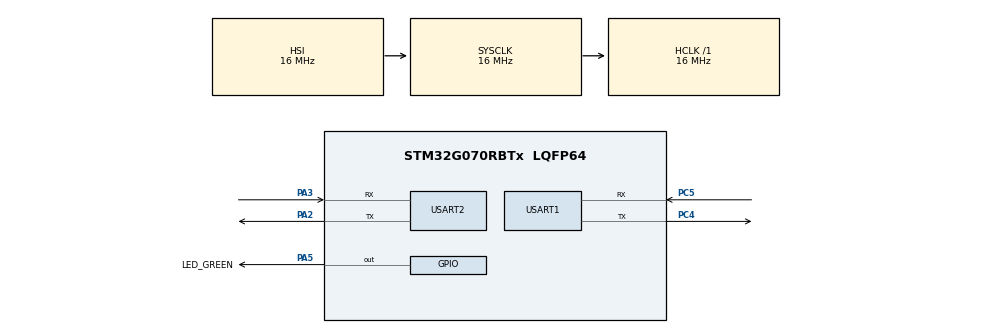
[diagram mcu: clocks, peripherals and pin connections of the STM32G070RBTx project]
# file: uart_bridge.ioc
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FREERTOS.MEMORY_ALLOCATION=2
FREERTOS.Queues01=q_to_uart1,32,uint8_t,0,Static,q_to_uart1Buffer,q_to_uart1ControlBlock;q_to_uart2,32,uint8_t,0,Static,q_to_uart2Buffer,q_to_uart2ControlBlock
FREERTOS.Tasks01=defaultTask,-2,128,StartDefaultTask,Default,NULL,Static,defaultTaskBuffer,defaultTaskControlBlock;uart1_task,0,128,uart1_task_ef,Default,NULL,Static,uart1_taskBuffer,uart1_taskControlBlock;uart2_task,0,128,uart2_task_ef,Default,NULL,Static,uart2_taskBuffer,uart2_taskControlBlock
FREERTOS.configTOTAL_HEAP_SIZE=4096
FREERTOS.configUSE_PREEMPTION=0
Mcu.Family=STM32G0
Mcu.Name=STM32G070RBTx
Mcu.Package=LQFP64
NVIC.TIM17_IRQn=true\:3\:0\:false\:false\:true\:false\:false\:true\:true
NVIC.TimeBase=TIM17_IRQn
NVIC.TimeBaseIP=TIM17
NVIC.USART1_IRQn=true\:3\:0\:true\:false\:true\:true\:true\:true\:true
NVIC.USART2_IRQn=true\:3\:0\:false\:false\:true\:true\:true\:true\:true
PA13.GPIO_Label=TMS
PA13.Mode=Serial_Wire
PA13.Signal=SYS_SWDIO
PA14-BOOT0.GPIO_Label=TCK
PA14-BOOT0.Mode=Serial_Wire
PA14-BOOT0.Signal=SYS_SWCLK
PA2.GPIO_PuPd=GPIO_PULLUP
PA2.Mode=Asynchronous
PA2.Signal=USART2_TX
PA3.GPIO_PuPd=GPIO_PULLUP
PA3.Mode=Asynchronous
PA3.Signal=USART2_RX
PA5.GPIO_Label=LED_GREEN
PA5.GPIO_Speed=GPIO_SPEED_FREQ_HIGH
PA5.Signal=GPIO_Output
PC13.Mode=SYS_WakeUp1
PC13.Signal=SYS_WKUP2
PC14-OSC32_IN\ (PC14).Mode=LSE-External-Oscillator
PC14-OSC32_IN\ (PC14).Signal=RCC_OSC32_IN
PC15-OSC32_OUT\ (PC15).Mode=LSE-External-Oscillator
PC15-OSC32_OUT\ (PC15).Signal=RCC_OSC32_OUT
PC4.Mode=Asynchronous
PC4.Signal=USART1_TX
PC5.Mode=Asynchronous
PC5.Signal=USART1_RX
PF0-OSC_IN\ (PF0).GPIO_Label=MCO
PF0-OSC_IN\ (PF0).Mode=HSE-External-Clock-Source
PF0-OSC_IN\ (PF0).Signal=RCC_OSC_IN
ProjectManager.HeapSize=0x2000
ProjectManager.StackSize=0x4000
ProjectManager.TargetToolchain=MDK-ARM V5.32
RCC.AHBFreq_Value=16000000
RCC.CortexFreq_Value=16000000
RCC.EXTERNAL_CLOCK_VALUE=12288000
RCC.HCLKFreq_Value=16000000
RCC.HSE_VALUE=8000000
RCC.HSI_VALUE=16000000
RCC.SYSCLKFreq_VALUE=16000000
RCC.VCOOutputFreq_Value=128000000
USART1.VirtualMode-Asynchronous=VM_ASYNC
USART2.VirtualMode-Asynchronous=VM_ASYNC
USART2.WordLength=WORDLENGTH_8B
VP_FREERTOS_VS_CMSIS_V1.Mode=CMSIS_V1
VP_SYS_VS_DBSignals.Mode=DisableDeadBatterySignals
VP_SYS_VS_tim17.Mode=TIM17
board=NUCLEO-G070RB

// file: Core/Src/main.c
/* USER CODE BEGIN Header */
/**
 ******************************************************************************
 * @file           : main.c
 * @brief          : Main program body
 ******************************************************************************
 * @attention
 *
 * Copyright (c) 2024 STMicroelectronics.
 * All rights reserved.
 *
 * This software is licensed under terms that can be found in the LICENSE file
 * in the root directory of this software component.
 * If no LICENSE file comes with this software, it is provided AS-IS.
 *
 ******************************************************************************
 */
/* USER CODE END Header */
#include "main.h"
#include "cmsis_os.h"

UART_HandleTypeDef huart1;
UART_HandleTypeDef huart2;

osThreadId defaultTaskHandle;
uint32_t defaultTaskBuffer[128];
osStaticThreadDef_t defaultTaskControlBlock;
osThreadId uart1_taskHandle;
uint32_t uart1_taskBuffer[128];
osStaticThreadDef_t uart1_taskControlBlock;
osThreadId uart2_taskHandle;
uint32_t uart2_taskBuffer[128];
osStaticThreadDef_t uart2_taskControlBlock;
osMessageQId q_to_uart1Handle;
uint8_t q_to_uart1Buffer[32 * sizeof(uint8_t)];
osStaticMessageQDef_t q_to_uart1ControlBlock;
osMessageQId q_to_uart2Handle;
uint8_t q_to_uart2Buffer[32 * sizeof(uint8_t)];
osStaticMessageQDef_t q_to_uart2ControlBlock;

void SystemClock_Config(void);
static void MX_GPIO_Init(void);
static void MX_USART1_UART_Init(void);
static void MX_USART2_UART_Init(void);
void StartDefaultTask(void const *argument);
void uart1_task_ef(void const *argument);
void uart2_task_ef(void const *argument);

int main(void)
{

  /* MCU Configuration--------------------------------------------------------*/

  /* Reset of all peripherals, Initializes the Flash interface and the Systick. */
  HAL_Init();

  /* Configure the system clock */
  SystemClock_Config();

  /* Initialize all configured peripherals */
  MX_GPIO_Init();
  MX_USART1_UART_Init();
  MX_USART2_UART_Init();

  /* Create the queue(s) */
  /* definition and creation of q_to_uart1 */
  osMessageQStaticDef(q_to_uart1, 32, uint8_t, q_to_uart1Buffer, &q_to_uart1ControlBlock);
  q_to_uart1Handle = osMessageCreate(osMessageQ(q_to_uart1), NULL);

  /* definition and creation of q_to_uart2 */
  osMessageQStaticDef(q_to_uart2, 32, uint8_t, q_to_uart2Buffer, &q_to_uart2ControlBlock);
  q_to_uart2Handle = osMessageCreate(osMessageQ(q_to_uart2), NULL);

  /* Create the thread(s) */
  /* definition and creation of defaultTask */
  osThreadStaticDef(defaultTask, StartDefaultTask, osPriorityLow, 0, 128, defaultTaskBuffer, &defaultTaskControlBlock);
  defaultTaskHandle = osThreadCreate(osThread(defaultTask), NULL);

  /* definition and creation of uart1_task */
  osThreadStaticDef(uart1_task, uart1_task_ef, osPriorityNormal, 0, 128, uart1_taskBuffer, &uart1_taskControlBlock);
  uart1_taskHandle = osThreadCreate(osThread(uart1_task), NULL);

  /* definition and creation of uart2_task */
  osThreadStaticDef(uart2_task, uart2_task_ef, osPriorityNormal, 0, 128, uart2_taskBuffer, &uart2_taskControlBlock);
  uart2_taskHandle = osThreadCreate(osThread(uart2_task), NULL);

  /* Start scheduler */
  osKernelStart();

  /* We should never get here as control is now taken by the scheduler */

  /* Infinite loop */
  while (1)
  {

  }
}

void SystemClock_Config(void)
{
  RCC_OscInitTypeDef RCC_OscInitStruct = {0};
  RCC_ClkInitTypeDef RCC_ClkInitStruct = {0};

  /** Configure the main internal regulator output voltage
   */
  HAL_PWREx_ControlVoltageScaling(PWR_REGULATOR_VOLTAGE_SCALE1);

  /** Initializes the RCC Oscillators according to the specified parameters
   * in the RCC_OscInitTypeDef structure.
   */
  RCC_OscInitStruct.OscillatorType = RCC_OSCILLATORTYPE_HSI;
  RCC_OscInitStruct.HSIState = RCC_HSI_ON;
  RCC_OscInitStruct.HSIDiv = RCC_HSI_DIV1;
  RCC_OscInitStruct.HSICalibrationValue = RCC_HSICALIBRATION_DEFAULT;
  RCC_OscInitStruct.PLL.PLLState = RCC_PLL_NONE;
  if (HAL_RCC_OscConfig(&RCC_OscInitStruct) != HAL_OK)
  {
    Error_Handler();
  }

  /** Initializes the CPU, AHB and APB buses clocks
   */
  RCC_ClkInitStruct.ClockType = RCC_CLOCKTYPE_HCLK | RCC_CLOCKTYPE_SYSCLK | RCC_CLOCKTYPE_PCLK1;
  RCC_ClkInitStruct.SYSCLKSource = RCC_SYSCLKSOURCE_HSI;
  RCC_ClkInitStruct.AHBCLKDivider = RCC_SYSCLK_DIV1;
  RCC_ClkInitStruct.APB1CLKDivider = RCC_HCLK_DIV1;

  if (HAL_RCC_ClockConfig(&RCC_ClkInitStruct, FLASH_LATENCY_0) != HAL_OK)
  {
    Error_Handler();
  }
}

static void MX_USART1_UART_Init(void)
{

  huart1.Instance = USART1;
  huart1.Init.BaudRate = 9600;
  huart1.Init.WordLength = UART_WORDLENGTH_8B;
  huart1.Init.StopBits = UART_STOPBITS_1;
  huart1.Init.Parity = UART_PARITY_NONE;
  huart1.Init.Mode = UART_MODE_TX_RX;
  huart1.Init.HwFlowCtl = UART_HWCONTROL_NONE;
  huart1.Init.OverSampling = UART_OVERSAMPLING_16;
  huart1.Init.OneBitSampling = UART_ONE_BIT_SAMPLE_DISABLE;
  huart1.Init.ClockPrescaler = UART_PRESCALER_DIV1;
  huart1.AdvancedInit.AdvFeatureInit = UART_ADVFEATURE_NO_INIT;
  if (HAL_UART_Init(&huart1) != HAL_OK)
  {
    Error_Handler();
  }
  if (HAL_UARTEx_SetTxFifoThreshold(&huart1, UART_TXFIFO_THRESHOLD_1_8) != HAL_OK)
  {
    Error_Handler();
  }
  if (HAL_UARTEx_SetRxFifoThreshold(&huart1, UART_RXFIFO_THRESHOLD_1_8) != HAL_OK)
  {
    Error_Handler();
  }
  if (HAL_UARTEx_DisableFifoMode(&huart1) != HAL_OK)
  {
    Error_Handler();
  }
}

static void MX_USART2_UART_Init(void)
{

  huart2.Instance = USART2;
  huart2.Init.BaudRate = 9600;
  huart2.Init.WordLength = UART_WORDLENGTH_8B;
  huart2.Init.StopBits = UART_STOPBITS_1;
  huart2.Init.Parity = UART_PARITY_NONE;
  huart2.Init.Mode = UART_MODE_TX_RX;
  huart2.Init.HwFlowCtl = UART_HWCONTROL_NONE;
  huart2.Init.OverSampling = UART_OVERSAMPLING_16;
  huart2.Init.OneBitSampling = UART_ONE_BIT_SAMPLE_DISABLE;
  huart2.Init.ClockPrescaler = UART_PRESCALER_DIV1;
  huart2.AdvancedInit.AdvFeatureInit = UART_ADVFEATURE_NO_INIT;
  if (HAL_UART_Init(&huart2) != HAL_OK)
  {
    Error_Handler();
  }
  if (HAL_UARTEx_SetTxFifoThreshold(&huart2, UART_TXFIFO_THRESHOLD_1_8) != HAL_OK)
  {
    Error_Handler();
  }
  if (HAL_UARTEx_SetRxFifoThreshold(&huart2, UART_RXFIFO_THRESHOLD_1_8) != HAL_OK)
  {
    Error_Handler();
  }
  if (HAL_UARTEx_DisableFifoMode(&huart2) != HAL_OK)
  {
    Error_Handler();
  }
}

static void MX_GPIO_Init(void)
{
  GPIO_InitTypeDef GPIO_InitStruct = {0};

  /* GPIO Ports Clock Enable */
  __HAL_RCC_GPIOC_CLK_ENABLE();
  __HAL_RCC_GPIOF_CLK_ENABLE();
  __HAL_RCC_GPIOA_CLK_ENABLE();
  __HAL_RCC_GPIOB_CLK_ENABLE();
  __HAL_RCC_GPIOD_CLK_ENABLE();

  /*Configure GPIO pin Output Level */
  HAL_GPIO_WritePin(LED_GREEN_GPIO_Port, LED_GREEN_Pin, GPIO_PIN_RESET);

  /*Configure GPIO pins : PC11 PC12 PC0 PC1
                           PC2 PC3 PC6 PC7
                           PC8 PC9 PC10 */
  GPIO_InitStruct.Pin = GPIO_PIN_11 | GPIO_PIN_12 | GPIO_PIN_0 | GPIO_PIN_1 | GPIO_PIN_2 | GPIO_PIN_3 | GPIO_PIN_6 | GPIO_PIN_7 | GPIO_PIN_8 | GPIO_PIN_9 | GPIO_PIN_10;
  GPIO_InitStruct.Mode = GPIO_MODE_ANALOG;
  GPIO_InitStruct.Pull = GPIO_NOPULL;
  HAL_GPIO_Init(GPIOC, &GPIO_InitStruct);

  /*Configure GPIO pin : PF1 */
  GPIO_InitStruct.Pin = GPIO_PIN_1;
  GPIO_InitStruct.Mode = GPIO_MODE_ANALOG;
  GPIO_InitStruct.Pull = GPIO_NOPULL;
  HAL_GPIO_Init(GPIOF, &GPIO_InitStruct);

  /*Configure GPIO pins : PA0 PA1 PA4 PA6
                           PA7 PA8 PA9 PA10
                           PA11 PA12 PA15 */
  GPIO_InitStruct.Pin = GPIO_PIN_0 | GPIO_PIN_1 | GPIO_PIN_4 | GPIO_PIN_6 | GPIO_PIN_7 | GPIO_PIN_8 | GPIO_PIN_9 | GPIO_PIN_10 | GPIO_PIN_11 | GPIO_PIN_12 | GPIO_PIN_15;
  GPIO_InitStruct.Mode = GPIO_MODE_ANALOG;
  GPIO_InitStruct.Pull = GPIO_NOPULL;
  HAL_GPIO_Init(GPIOA, &GPIO_InitStruct);

  /*Configure GPIO pin : LED_GREEN_Pin */
  GPIO_InitStruct.Pin = LED_GREEN_Pin;
  GPIO_InitStruct.Mode = GPIO_MODE_OUTPUT_PP;
  GPIO_InitStruct.Pull = GPIO_NOPULL;
  GPIO_InitStruct.Speed = GPIO_SPEED_FREQ_HIGH;
  HAL_GPIO_Init(LED_GREEN_GPIO_Port, &GPIO_InitStruct);

  /*Configure GPIO pins : PB0 PB1 PB2 PB10
                           PB11 PB12 PB13 PB14
                           PB15 PB3 PB4 PB5
                           PB6 PB7 PB8 PB9 */
  GPIO_InitStruct.Pin = GPIO_PIN_0 | GPIO_PIN_1 | GPIO_PIN_2 | GPIO_PIN_10 | GPIO_PIN_11 | GPIO_PIN_12 | GPIO_PIN_13 | GPIO_PIN_14 | GPIO_PIN_15 | GPIO_PIN_3 | GPIO_PIN_4 | GPIO_PIN_5 | GPIO_PIN_6 | GPIO_PIN_7 | GPIO_PIN_8 | GPIO_PIN_9;
  GPIO_InitStruct.Mode = GPIO_MODE_ANALOG;
  GPIO_InitStruct.Pull = GPIO_NOPULL;
  HAL_GPIO_Init(GPIOB, &GPIO_InitStruct);

  /*Configure GPIO pins : PD8 PD9 PD0 PD1
                           PD2 PD3 PD4 PD5
                           PD6 */
  GPIO_InitStruct.Pin = GPIO_PIN_8 | GPIO_PIN_9 | GPIO_PIN_0 | GPIO_PIN_1 | GPIO_PIN_2 | GPIO_PIN_3 | GPIO_PIN_4 | GPIO_PIN_5 | GPIO_PIN_6;
  GPIO_InitStruct.Mode = GPIO_MODE_ANALOG;
  GPIO_InitStruct.Pull = GPIO_NOPULL;
  HAL_GPIO_Init(GPIOD, &GPIO_InitStruct);

}

void StartDefaultTask(void const *argument)
{
  /* USER CODE BEGIN 5 */
  /* Infinite loop */
  for (;;)
  {
    HAL_GPIO_TogglePin(LED_GREEN_GPIO_Port, LED_GREEN_Pin);
    osDelay(1000);
  }
  /* USER CODE END 5 */
}

void uart1_task_ef(void const *argument)
{
  osDelay(10);
  static HAL_StatusTypeDef stat = HAL_OK;
  static uint8_t buf_uart1 = 0;
  static uint8_t buf_uart1_tx = 0;
  uint32_t ulNotificationValue = 0;

  for (;;)
  {

    stat = HAL_UART_Receive_IT(&huart1, &buf_uart1, sizeof(buf_uart1));
    if (stat != HAL_OK)
    {
      //printf("UART1 receive error=%u\n", stat);
      Error_Handler();
    }
    ulNotificationValue = ulTaskNotifyTake(0, portMAX_DELAY);
    if (ulNotificationValue == 1) // пришел пинок от оповещения
    {
      buf_uart1_tx=buf_uart1;
      HAL_UART_Transmit_IT(&huart2, &buf_uart1_tx, sizeof(buf_uart1_tx));
      continue;
    }
    else
    {
      /* Таймаут вызова ulTaskNotifyTake(). */
      continue;
    }
  }
}

void uart2_task_ef(void const *argument)
{
  osDelay(10);
  static HAL_StatusTypeDef stat = HAL_OK;
  static uint8_t buf_uart2 = 0;
  static uint8_t buf_uart2_tx = 0;
  uint32_t ulNotificationValue = 0;

  for (;;)
  {

    stat = HAL_UART_Receive_IT(&huart2, &buf_uart2, sizeof(buf_uart2));
    if (stat != HAL_OK) // если не получилось запуститься - ждем и перезапускаемся
    {
      //printf("UART1 receive error=%u\n", stat);
      Error_Handler();
    }
    ulNotificationValue = ulTaskNotifyTake(0, portMAX_DELAY);
    if (ulNotificationValue == 1) // пришел пинок от оповещения
    {
      buf_uart2_tx=buf_uart2;
      HAL_UART_Transmit_IT(&huart1, &buf_uart2_tx, sizeof(buf_uart2_tx));
      continue;
    }
    else
    {
      /* Таймаут вызова ulTaskNotifyTake(). */
      continue;
    }
  }
}

void HAL_TIM_PeriodElapsedCallback(TIM_HandleTypeDef *htim)
{
  if (htim->Instance == TIM17)
  {
    HAL_IncTick();
  }
}

void Error_Handler(void)
{
  __disable_irq();
  while (1)
  {
  }
}

/**
 * @brief  Rx Transfer completed callbacks.
 * @param  huart  Pointer to a UART_HandleTypeDef structure that contains
 *                the configuration information for the specified UART module.
 * @retval None
 */
void HAL_UART_RxCpltCallback(UART_HandleTypeDef *huart)
{

  if (huart->Instance == USART1)
  {
    xTaskNotifyGive(uart1_taskHandle);
  }
  else if (huart->Instance == USART2)
  {
    xTaskNotifyGive(uart2_taskHandle);
  }
  else
  {
    Error_Handler();
  }
}
